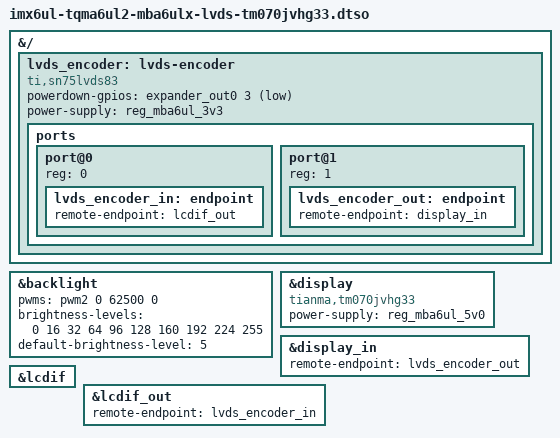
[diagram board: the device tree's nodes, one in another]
// SPDX-License-Identifier: (GPL-2.0-or-later OR MIT)
/*
 * Copyright 2018-2026 TQ-Systems GmbH <linux@ew.tq-group.com>,
 * D-82229 Seefeld, Germany.
 * Author: Markus Niebel
 * Author: Alexander Stein
 */

/dts-v1/;
/plugin/;

#include <dt-bindings/gpio/gpio.h>

&{/} {
	lvds_encoder: lvds-encoder {
		compatible = "ti,sn75lvds83", "lvds-encoder";
		powerdown-gpios = <&expander_out0 3 GPIO_ACTIVE_LOW>;
		power-supply = <&reg_mba6ul_3v3>;

		ports {
			#address-cells = <1>;
			#size-cells = <0>;

			port@0 {
				reg = <0>;

				lvds_encoder_in: endpoint {
					remote-endpoint = <&lcdif_out>;
				};
			};

			port@1 {
				reg = <1>;

				lvds_encoder_out: endpoint {
					remote-endpoint = <&display_in>;
				};
			};
		};
	};
};

&backlight {
	pwms = <&pwm2 0 62500 0>;
	brightness-levels = <0 16 32 64 96 128 160 192 224 255>;
	default-brightness-level = <5>;
	status = "okay";
};

&display {
	compatible = "tianma,tm070jvhg33";
	power-supply = <&reg_mba6ul_5v0>;
	status = "okay";
};

&display_in {
	remote-endpoint = <&lvds_encoder_out>;
};

/* for lcd reset != #stkrst */
/* place r2021, resolder r2022 and iomux following: */
/* MX6UL_PAD_LCD_RESET__GPIO3_IO04	0x79 */
&lcdif {
	status = "okay";
};

&lcdif_out {
	remote-endpoint = <&lvds_encoder_in>;
};
